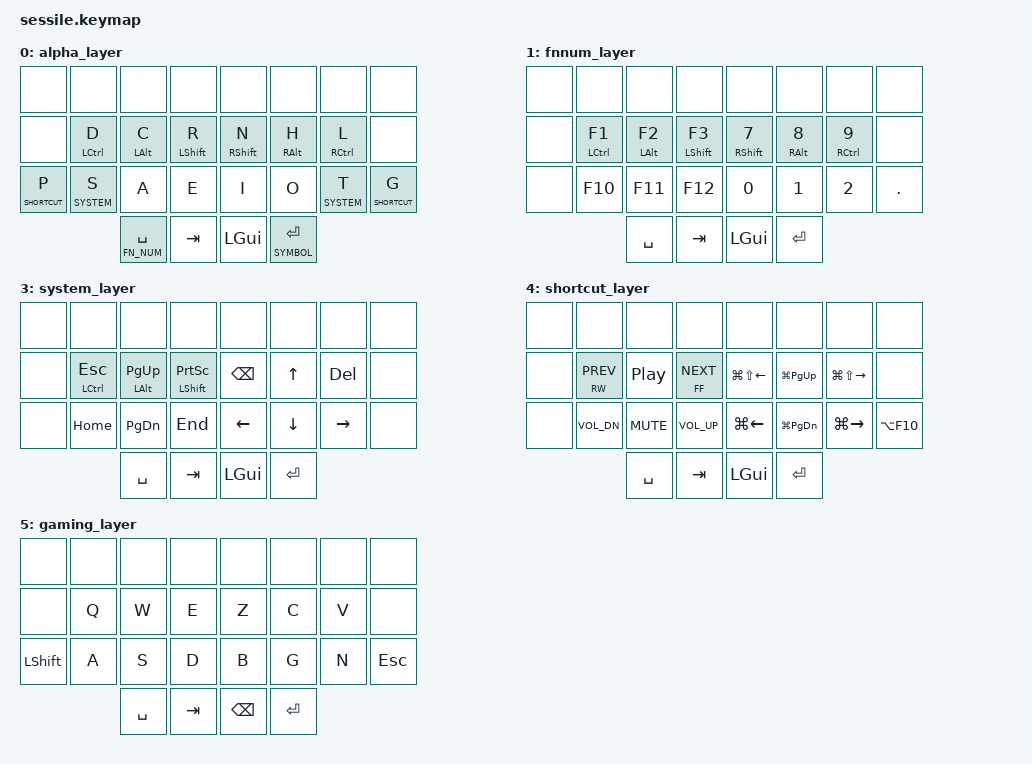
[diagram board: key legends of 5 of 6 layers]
/*
* Copyright (c) 2020 The ZMK Contributors
*
* SPDX-License-Identifier: MIT
*/

#define ALPHA 0
#define FN_NUM 1
#define SYMBOL 2
#define SYSTEM 3
#define SHORTCUT 4
#define GAMING 5

#include <behaviors.dtsi>
#include <behaviors/num_word.dtsi>
#include <dt-bindings/zmk/keys.h>
#include <dt-bindings/zmk/bt.h>
#include <dt-bindings/zmk/outputs.h>
#include <zmk-helpers/helper.h>
#include "28.h"
#include "behaviors.dtsi"
#include "combos.dtsi"

/ {
	keymap {
		compatible = "zmk,keymap";
		alpha_layer {
			bindings = <
			&none			&none			&none			&none					&none			&none			&none			&none
			&none			&mt LCTRL D  	&mt LALT C 		&mt LSHFT R  	 		&mt RSHFT N		&mt RALT H		&mt RCTRL L		&none
			&lt SHORTCUT P	&lt SYSTEM S	&kp A			&kp E					&kp I			&kp O			&lt SYSTEM T	&lt SHORTCUT G
											&lt FN_NUM SPACE &kp TAB 				&kp LGUI		&lt SYMBOL RET
			>;
		};
		fnnum_layer {
			bindings = <
			&none		&none			&none			&none					&none			&none			&none			&none
			&none		&mt LCTRL F1  	&mt LALT F2		&mt LSHFT F3  	 		&mt RSHFT N7	&mt RALT N8		&mt RCTRL N9	&none
			&none		&kp F10			&kp F11			&kp F12					&kp N0			&kp N1			&kp N2			&kp DOT
										&kp SPACE   	&kp TAB 				&kp LGUI		&kp RET
			>;
		};
		symbol_layer {
			bindings = <
			&none		&none			&none				&none							&none					&none				&none					&none
			&none		&mt LCTRL GRAVE	&mt_bslh LALT &none	&mt_under LSHFT &none			&mt_minus RSHFT &none	&mt_slsh RALT &none	&mt_equal RCTRL &none	&none
			&kp AT		&kp HASH		&dollar				&ampersand						&dot					&comma				&kp SQT					&none
										&kp SPACE   		&kp TAB 						&kp LGUI				&kp RET
			>;
		};
		system_layer {
			bindings = <
			&none		&none			&none			&none					&none			&none			&none			&none
			&none		&mt LCTRL ESC	&mt LALT PG_UP	&mt LSHFT PSCRN			&kp BSPC		&kp UP			&kp DEL			&none
			&none		&kp HOME		&kp PG_DN		&kp END					&kp LEFT		&kp DOWN		&kp RIGHT		&none
										&kp SPACE   	&kp TAB 				&kp LGUI		&kp RET
			>;
		};
		shortcut_layer {
			bindings = <
			&none		&none			&none			&none					&none				&none				&none				&none
			&none		&mt C_RW C_PREV	&kp C_PP		&mt C_FF C_NEXT			&kp LG(LS(LEFT))	&kp LG(PG_UP)		&kp LG(LS(RIGHT))	&none
			&none		&kp C_VOL_DN	&kp C_MUTE		&kp C_VOL_UP			&kp LG(LEFT)		&kp LG(PG_DN)		&kp LG(RIGHT)		&kp LA(F10)
										&kp SPACE   	&kp TAB 				&kp LGUI			&kp RET
			>;
		};
		gaming_layer {
			bindings = <
			&none		&none		&none		&none				&none		&none		&none		&none
			&none		&kp Q		&kp W		&kp E				&kp Z		&kp C		&kp V		&none
			&kp LSHFT	&kp A		&kp S		&kp D				&kp B		&kp G		&kp N		&kp ESC
									&kp SPACE	&kp TAB				&kp BSPC	&kp RET
			>;
		};
	};
};
